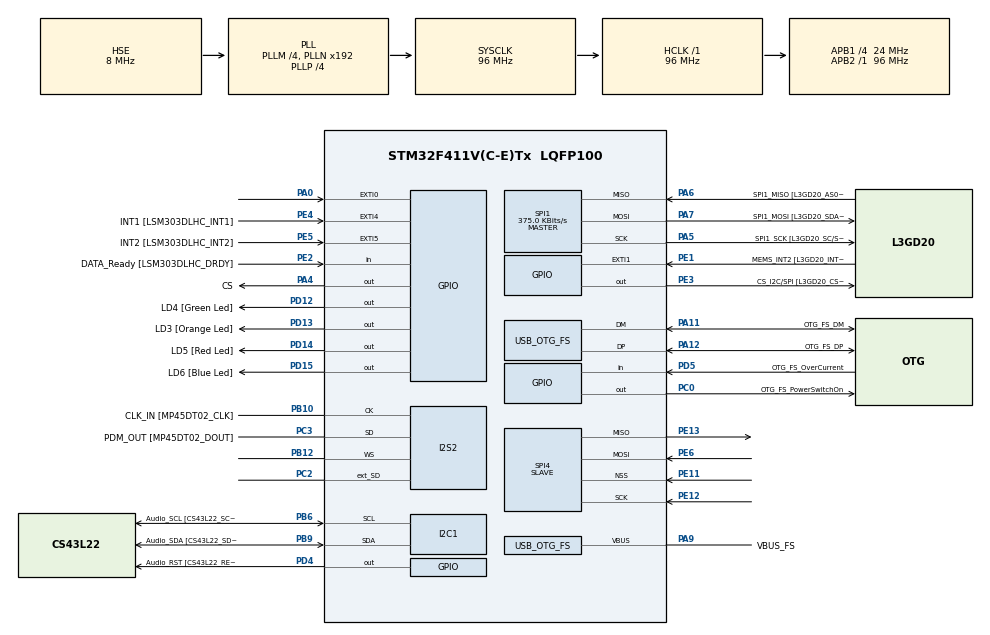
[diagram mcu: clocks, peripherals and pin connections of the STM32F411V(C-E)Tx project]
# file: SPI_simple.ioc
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Dma.Request0=SPI4_RX
Dma.SPI4_RX.0.Direction=DMA_PERIPH_TO_MEMORY
Dma.SPI4_RX.0.FIFOMode=DMA_FIFOMODE_DISABLE
Dma.SPI4_RX.0.Instance=DMA2_Stream0
Dma.SPI4_RX.0.MemDataAlignment=DMA_MDATAALIGN_BYTE
Dma.SPI4_RX.0.MemInc=DMA_MINC_ENABLE
Dma.SPI4_RX.0.Mode=DMA_CIRCULAR
Dma.SPI4_RX.0.PeriphDataAlignment=DMA_PDATAALIGN_BYTE
Dma.SPI4_RX.0.PeriphInc=DMA_PINC_DISABLE
Dma.SPI4_RX.0.Priority=DMA_PRIORITY_LOW
I2S2.AudioFreq=I2S_AUDIOFREQ_96K
I2S2.ErrorAudioFreq=0.15 %
I2S2.FullDuplexMode=I2S_FULLDUPLEXMODE_ENABLE
I2S2.Instance=SPI$Index
I2S2.RealAudioFreq=96.153 KHz
I2S2.VirtualMode=I2S_MODE_MASTER
Mcu.Family=STM32F4
Mcu.Name=STM32F411V(C-E)Tx
Mcu.Package=LQFP100
NVIC.DMA2_Stream0_IRQn=true\:0\:0\:false\:false\:true\:false\:true\:true
NVIC.OTG_FS_IRQn=true\:0\:0\:false\:false\:true\:true\:true\:true
NVIC.PriorityGroup=NVIC_PRIORITYGROUP_0
NVIC.SPI1_IRQn=true\:0\:0\:false\:false\:true\:true\:true\:true
NVIC.SPI4_IRQn=true\:0\:0\:false\:false\:true\:true\:true\:true
PA0-WKUP.GPIO_ModeDefaultEXTI=GPIO_MODE_EVT_RISING
PA0-WKUP.Signal=GPXTI0
PA10.GPIO_Label=OTG_FS_ID
PA10.Signal=USB_OTG_FS_ID
PA11.GPIO_Label=OTG_FS_DM
PA11.Mode=Host_Only
PA11.Signal=USB_OTG_FS_DM
PA12.GPIO_Label=OTG_FS_DP
PA12.Mode=Host_Only
PA12.Signal=USB_OTG_FS_DP
PA13.GPIO_Label=SWDIO
PA13.Mode=Serial_Wire
PA13.Signal=SYS_JTMS-SWDIO
PA14.GPIO_Label=SWCLK
PA14.Mode=Serial_Wire
PA14.Signal=SYS_JTCK-SWCLK
PA4.GPIO_Label=CS
PA4.Signal=GPIO_Output
PA5.GPIO_Label=SPI1_SCK [L3GD20_SC/SPC]
PA5.Mode=Full_Duplex_Master
PA5.Signal=SPI1_SCK
PA6.GPIO_Label=SPI1_MISO [L3GD20_AS0/SDO]
PA6.Mode=Full_Duplex_Master
PA6.Signal=SPI1_MISO
PA7.GPIO_Label=SPI1_MOSI [L3GD20_SDA/SDI/SDO]
PA7.Mode=Full_Duplex_Master
PA7.Signal=SPI1_MOSI
PA9.GPIO_Label=VBUS_FS
PA9.Mode=Activate_VBUS
PA9.Signal=USB_OTG_FS_VBUS
PB10.GPIO_Label=CLK_IN [MP45DT02_CLK]
PB10.Mode=Full_Duplex_Master
PB10.Signal=I2S2_CK
PB12.Mode=Full_Duplex_Master
PB12.Signal=I2S2_WS
PB3.GPIO_Label=SWO
PB3.Signal=SYS_JTDO-SWO
PB6.GPIO_Label=Audio_SCL [CS43L22_SCL]
PB6.GPIO_Mode=GPIO_MODE_AF_OD
PB6.GPIO_Pu=GPIO_PULLUP
PB6.GPIO_PuPd=GPIO_NOPULL
PB6.GPIO_Speed=GPIO_SPEED_FREQ_LOW
PB6.Mode=I2C
PB6.Signal=I2C1_SCL
PB9.GPIO_Label=Audio_SDA [CS43L22_SDA]
PB9.GPIO_Mode=GPIO_MODE_AF_OD
PB9.GPIO_Pu=GPIO_PULLUP
PB9.GPIO_PuPd=GPIO_NOPULL
PB9.GPIO_Speed=GPIO_SPEED_FREQ_LOW
PB9.Mode=I2C
PB9.Signal=I2C1_SDA
PC0.GPIO_Label=OTG_FS_PowerSwitchOn
PC0.PinState=GPIO_PIN_SET
PC0.Signal=GPIO_Output
PC10.GPIO_Label=I2S3_SCK [CS43L22_SCLK]
PC10.GPIO_Mode=GPIO_MODE_AF_PP
PC10.GPIO_PuPd=GPIO_NOPULL
PC10.GPIO_Speed=GPIO_SPEED_FREQ_LOW
PC10.Signal=I2S3_CK
PC12.GPIO_Label=I2S3_SD [CS43L22_SDIN]
PC12.GPIO_Mode=GPIO_MODE_AF_PP
PC12.GPIO_PuPd=GPIO_NOPULL
PC12.GPIO_Speed=GPIO_SPEED_FREQ_LOW
PC12.Signal=I2S3_SD
PC14-OSC32_IN.GPIO_Label=PC14-OSC32_IN
PC14-OSC32_IN.Mode=LSE-External-Oscillator
PC14-OSC32_IN.Signal=RCC_OSC32_IN
PC15-OSC32_OUT.GPIO_Label=PC15-OSC32_OUT
PC15-OSC32_OUT.Mode=LSE-External-Oscillator
PC15-OSC32_OUT.Signal=RCC_OSC32_OUT
PC2.Mode=Full_Duplex_Master
PC2.Signal=I2S2_ext_SD
PC3.GPIO_Label=PDM_OUT [MP45DT02_DOUT]
PC3.Mode=Full_Duplex_Master
PC3.Signal=I2S2_SD
PC7.GPIO_Label=I2S3_MCK [CS43L22_MCLK]
PC7.GPIO_Mode=GPIO_MODE_AF_PP
PC7.GPIO_PuPd=GPIO_NOPULL
PC7.GPIO_Speed=GPIO_SPEED_FREQ_LOW
PC7.Signal=I2S3_MCK
PD12.GPIO_Label=LD4 [Green Led]
PD12.GPIO_PuPd=GPIO_NOPULL
PD12.GPIO_Speed=GPIO_SPEED_FREQ_LOW
PD12.Signal=GPIO_Output
PD13.GPIO_Label=LD3 [Orange Led]
PD13.GPIO_PuPd=GPIO_NOPULL
PD13.GPIO_Speed=GPIO_SPEED_FREQ_LOW
PD13.Signal=GPIO_Output
PD14.GPIO_Label=LD5 [Red Led]
PD14.GPIO_PuPd=GPIO_NOPULL
PD14.GPIO_Speed=GPIO_SPEED_FREQ_LOW
PD14.Signal=GPIO_Output
PD15.GPIO_Label=LD6 [Blue Led]
PD15.GPIO_PuPd=GPIO_NOPULL
PD15.GPIO_Speed=GPIO_SPEED_FREQ_LOW
PD15.Signal=GPIO_Output
PD4.GPIO_Label=Audio_RST [CS43L22_RESET]
PD4.Signal=GPIO_Output
PD5.GPIO_Label=OTG_FS_OverCurrent
PD5.Signal=GPIO_Input
PE1.GPIO_Label=MEMS_INT2 [L3GD20_INT2]
PE1.GPIO_ModeDefaultEXTI=GPIO_MODE_EVT_RISING
PE1.Signal=GPXTI1
PE11.Mode=NSS_Signal_Hard_Input
PE11.Signal=SPI4_NSS
PE12.Mode=Full_Duplex_Slave
PE12.Signal=SPI4_SCK
PE13.Mode=Full_Duplex_Slave
PE13.Signal=SPI4_MISO
PE2.GPIO_Label=DATA_Ready [LSM303DLHC_DRDY]
PE2.Signal=GPIO_Input
PE3.GPIO_Label=CS_I2C/SPI [L3GD20_CS_I2C/SPI]
PE3.Signal=GPIO_Output
PE4.GPIO_Label=INT1 [LSM303DLHC_INT1]
PE4.GPIO_ModeDefaultEXTI=GPIO_MODE_EVT_RISING
PE4.Signal=GPXTI4
PE5.GPIO_Label=INT2 [LSM303DLHC_INT2]
PE5.GPIO_ModeDefaultEXTI=GPIO_MODE_EVT_RISING
PE5.Signal=GPXTI5
PE6.Mode=Full_Duplex_Slave
PE6.Signal=SPI4_MOSI
PH0\ -\ OSC_IN.GPIO_Label=PH0-OSC_IN
PH0\ -\ OSC_IN.Mode=HSE-External-Oscillator
PH0\ -\ OSC_IN.Signal=RCC_OSC_IN
PH1\ -\ OSC_OUT.GPIO_Label=PH1-OSC_OUT
PH1\ -\ OSC_OUT.Mode=HSE-External-Oscillator
PH1\ -\ OSC_OUT.Signal=RCC_OSC_OUT
ProjectManager.HeapSize=0x200
ProjectManager.StackSize=0x400
ProjectManager.TargetToolchain=Makefile
RCC.48MHZClocksFreq_Value=48000000
RCC.AHBFreq_Value=96000000
RCC.APB1CLKDivider=RCC_HCLK_DIV4
RCC.APB1Freq_Value=24000000
RCC.APB1TimFreq_Value=48000000
RCC.APB2Freq_Value=96000000
RCC.APB2TimFreq_Value=96000000
RCC.CortexFreq_Value=96000000
RCC.HCLKFreq_Value=96000000
RCC.HSE_VALUE=8000000
RCC.HSI_VALUE=16000000
RCC.PLLI2SM=5
RCC.PLLI2SN=200
RCC.PLLM=4
RCC.PLLP=RCC_PLLP_DIV4
RCC.PLLQ=8
RCC.SYSCLKFreq_VALUE=96000000
RCC.SYSCLKSource=RCC_SYSCLKSOURCE_PLLCLK
RCC.VCOOutputFreq_Value=384000000
SPI1.BaudRatePrescaler=SPI_BAUDRATEPRESCALER_256
SPI1.CalculateBaudRate=375.0 KBits/s
SPI1.Direction=SPI_DIRECTION_2LINES
SPI1.Mode=SPI_MODE_MASTER
SPI1.VirtualType=VM_MASTER
SPI4.Direction=SPI_DIRECTION_2LINES
SPI4.Mode=SPI_MODE_SLAVE
SPI4.VirtualNSS=VM_NSSHARD
SPI4.VirtualType=VM_SLAVE
USB_HOST.BSP.number=1
USB_HOST.USBH_HandleTypeDef=hUsbHostFS
USB_HOST.VirtualModeFS=Cdc
USB_HOST0.BSP.STBoard=false
USB_HOST0.BSP.api=Unknown
USB_HOST0.BSP.instance=PC0
USB_HOST0.BSP.ip=GPIO
USB_HOST0.BSP.mode=Output
USB_HOST0.BSP.name=Drive_VBUS_FS
USB_HOST0.BSP.solution=PC0
USB_OTG_FS.VirtualMode=Host_Only
USB_OTG_FS.phy_itface=HCD_PHY_EMBEDDED
VP_USB_HOST_VS_USB_HOST_CDC_FS.Mode=CDC_FS
board=STM32F411E-DISCO

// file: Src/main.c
/* USER CODE BEGIN Header */
/**
  ******************************************************************************
  * @file           : main.c
  * @brief          : Main program body
  ******************************************************************************
  F411 Disco init default

  In this example I will use SPI1 run in mode Master (NSS pin controlled by software)
  to send data. SPI4 runs in mode Slave (NSS pin controlled by hardware) receive data
  using Interrupt (comment out) or DMA.

  SPI1 <-> SPI4 Connection:
    PA5 (SCK)  <-> PE12 (SCK)
    PA6 (MISO) <-> PE13 (MISO)
    PA7 (MOSI) <-> PE6 (MOSI)
    CS  (PA4)  <-> PE11 (NSS)
  ******************************************************************************
  */
/* USER CODE END Header */
#include "main.h"
#include "dma.h"
#include "i2c.h"
#include "i2s.h"
#include "spi.h"
#include "usb_host.h"
#include "gpio.h"

/* USER CODE BEGIN Includes */
#include <string.h>
/* USER CODE END Includes */

/* USER CODE BEGIN PD */
#define spi_enable    HAL_GPIO_WritePin(CS_GPIO_Port, CS_Pin, GPIO_PIN_RESET)
#define spi_disable   HAL_GPIO_WritePin(CS_GPIO_Port, CS_Pin, GPIO_PIN_SET)
/* USER CODE END PD */

/* USER CODE BEGIN PV */
// Interrupt mode
// char Tx_master[] = "Hello World\n";
// char Rx_slave[] = {0};
// char Rx_slave_buffer[20] = {0};
// uint8_t RxBufferIndex = 0;

uint8_t send_data = 32, receive_data = 0;
/* USER CODE END PV */

void SystemClock_Config(void);
void MX_USB_HOST_Process(void);

/* USER CODE BEGIN 0 */
// Interrupt Mode
// void HAL_SPI_RxCpltCallback(SPI_HandleTypeDef *hspi) {
//   HAL_GPIO_WritePin(LD3_GPIO_Port, LD3_Pin, GPIO_PIN_SET);

//   UNUSED(hspi);
//   if(hspi->Instance == SPI4) {
//     HAL_SPI_Receive_IT(&hspi4, (uint8_t*)Rx_slave, 1);
//     Rx_slave_buffer[RxBufferIndex++] = Rx_slave[0];
//     if(Rx_slave[0] == '\n')
//       RxBufferIndex = 0;
//   }
// }

// DMA mode
void HAL_SPI_TxCpltCallback(SPI_HandleTypeDef *hspi) {
  if(hspi->Instance == hspi1.Instance) {
    spi_disable;  // release the SPI slave in case other mcus want to access
    HAL_GPIO_TogglePin(LD3_GPIO_Port, LD3_Pin);
  }
}
/* USER CODE END 0 */

int main(void)
{

  /* MCU Configuration--------------------------------------------------------*/

  /* Reset of all peripherals, Initializes the Flash interface and the Systick. */
  HAL_Init();

  /* Configure the system clock */
  SystemClock_Config();

  /* Initialize all configured peripherals */
  MX_GPIO_Init();
  MX_DMA_Init();
  MX_I2C1_Init();
  MX_I2S2_Init();
  MX_SPI1_Init();
  MX_SPI4_Init();
  MX_USB_HOST_Init();
  /* USER CODE BEGIN 2 */
  // Interrupt mode
  // HAL_SPI_Receive_IT(&hspi4, (uint8_t*)Rx_slave, 1);
  // HAL_SPI_Transmit(&hspi1, (uint8_t*)Tx_master, strlen(Tx_master), 1000);
  HAL_SPI_Receive_DMA(&hspi4, &receive_data, 1);
  /* USER CODE END 2 */

  /* Infinite loop */
  while (1)
  {
    MX_USB_HOST_Process();

    /* USER CODE BEGIN 3 */
    spi_enable;
    HAL_SPI_Transmit_IT(&hspi1, &send_data, 1);
    send_data++;
    HAL_Delay(1000);
  }
  /* USER CODE END 3 */
}

void SystemClock_Config(void)
{
  RCC_OscInitTypeDef RCC_OscInitStruct = {0};
  RCC_ClkInitTypeDef RCC_ClkInitStruct = {0};

  /** Configure the main internal regulator output voltage
  */
  __HAL_RCC_PWR_CLK_ENABLE();
  __HAL_PWR_VOLTAGESCALING_CONFIG(PWR_REGULATOR_VOLTAGE_SCALE1);

  /** Initializes the RCC Oscillators according to the specified parameters
  * in the RCC_OscInitTypeDef structure.
  */
  RCC_OscInitStruct.OscillatorType = RCC_OSCILLATORTYPE_HSE;
  RCC_OscInitStruct.HSEState = RCC_HSE_ON;
  RCC_OscInitStruct.PLL.PLLState = RCC_PLL_ON;
  RCC_OscInitStruct.PLL.PLLSource = RCC_PLLSOURCE_HSE;
  RCC_OscInitStruct.PLL.PLLM = 4;
  RCC_OscInitStruct.PLL.PLLN = 192;
  RCC_OscInitStruct.PLL.PLLP = RCC_PLLP_DIV4;
  RCC_OscInitStruct.PLL.PLLQ = 8;
  if (HAL_RCC_OscConfig(&RCC_OscInitStruct) != HAL_OK)
  {
    Error_Handler();
  }

  /** Initializes the CPU, AHB and APB buses clocks
  */
  RCC_ClkInitStruct.ClockType = RCC_CLOCKTYPE_HCLK|RCC_CLOCKTYPE_SYSCLK
                              |RCC_CLOCKTYPE_PCLK1|RCC_CLOCKTYPE_PCLK2;
  RCC_ClkInitStruct.SYSCLKSource = RCC_SYSCLKSOURCE_PLLCLK;
  RCC_ClkInitStruct.AHBCLKDivider = RCC_SYSCLK_DIV1;
  RCC_ClkInitStruct.APB1CLKDivider = RCC_HCLK_DIV4;
  RCC_ClkInitStruct.APB2CLKDivider = RCC_HCLK_DIV1;

  if (HAL_RCC_ClockConfig(&RCC_ClkInitStruct, FLASH_LATENCY_3) != HAL_OK)
  {
    Error_Handler();
  }
}

void Error_Handler(void)
{
  __disable_irq();
  while (1)
  {
  }
}
